VERSION ""

NS_ :

BS_:

BU_:

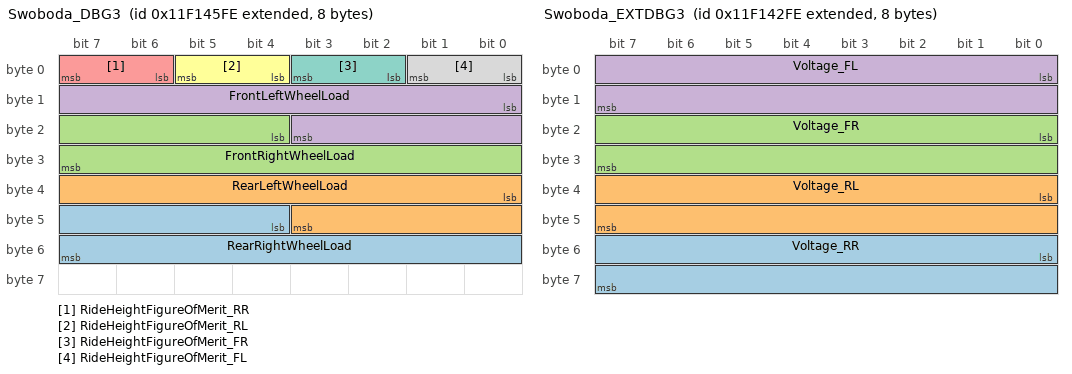
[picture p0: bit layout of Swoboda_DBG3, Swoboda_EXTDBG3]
BO_ 2448508414 Swoboda_DBG3: 8 Vector__XXX
 SG_ RearRightWheelLoad : 44|12@1+ (1,0) [0|4095] "" Vector__XXX
 SG_ RearLeftWheelLoad : 32|12@1+ (1,0) [0|4095] "" Vector__XXX
 SG_ FrontRightWheelLoad : 20|12@1+ (1,0) [0|4095] "" Vector__XXX
 SG_ FrontLeftWheelLoad : 8|12@1+ (1,0) [0|4095] "" Vector__XXX
 SG_ RideHeightFigureOfMerit_RR : 6|2@1+ (1,0) [0|3] "" Vector__XXX
 SG_ RideHeightFigureOfMerit_RL : 4|2@1+ (1,0) [0|3] "" Vector__XXX
 SG_ RideHeightFigureOfMerit_FR : 2|2@1+ (1,0) [0|3] "" Vector__XXX
 SG_ RideHeightFigureOfMerit_FL : 0|2@1+ (1,0) [0|3] "" Vector__XXX

BO_ 2448507646 Swoboda_EXTDBG3: 8 Vector__XXX
 SG_ Voltage_RR : 48|16@1+ (0.0001,0) [0|6.5535] "V" Vector__XXX
 SG_ Voltage_RL : 32|16@1+ (0.0001,0) [0|6.5535] "V" Vector__XXX
 SG_ Voltage_FR : 16|16@1+ (0.0001,0) [0|6.5535] "V" Vector__XXX
 SG_ Voltage_FL : 0|16@1+ (0.0001,0) [0|6.5535] "V" Vector__XXX

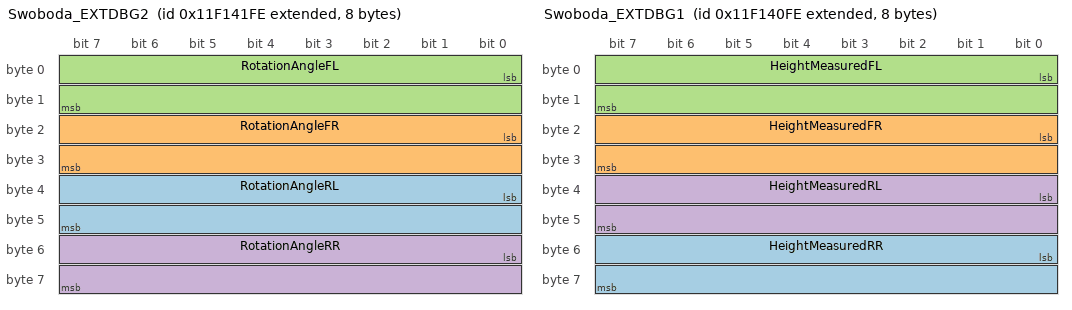
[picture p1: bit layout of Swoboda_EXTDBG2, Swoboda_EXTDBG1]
BO_ 2448507390 Swoboda_EXTDBG2: 8 Vector__XXX
 SG_ RotationAngleRL : 32|16@1+ (0.01,0) [0|360] "deg" Vector__XXX
 SG_ RotationAngleFR : 16|16@1+ (0.01,0) [0|360] "deg" Vector__XXX
 SG_ RotationAngleFL : 0|16@1+ (0.01,0) [0|360] "deg" Vector__XXX
 SG_ RotationAngleRR : 48|16@1+ (0.01,0) [0|360] "deg" Vector__XXX

BO_ 2448507134 Swoboda_EXTDBG1: 8 Vector__XXX
 SG_ HeightMeasuredRR : 48|16@1- (0.01,0) [-327.68|327.67] "mm" Vector__XXX
 SG_ HeightMeasuredFR : 16|16@1- (0.01,0) [-327.68|327.67] "mm" Vector__XXX
 SG_ HeightMeasuredFL : 0|16@1- (0.01,0) [-327.68|327.67] "mm" Vector__XXX
 SG_ HeightMeasuredRL : 32|16@1- (0.01,0) [-327.68|327.67] "mm" Vector__XXX

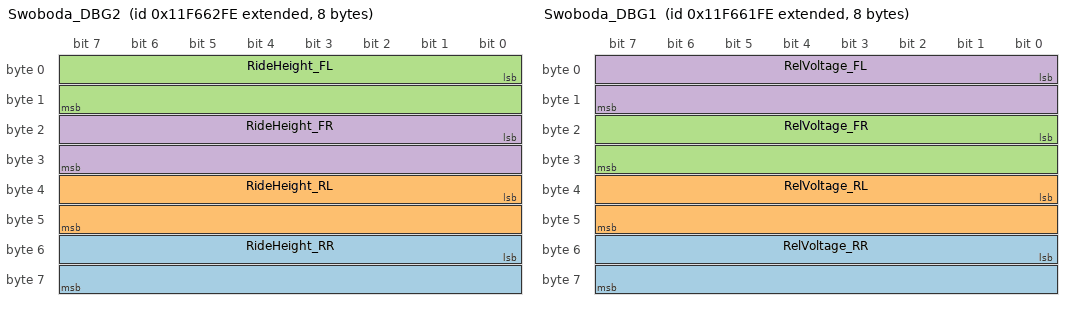
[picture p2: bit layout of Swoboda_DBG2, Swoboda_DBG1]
BO_ 2448843518 Swoboda_DBG2: 8 Vector__XXX
 SG_ RideHeight_RR : 48|16@1- (0.01,0) [-327.68|327.67] "mm" Vector__XXX
 SG_ RideHeight_RL : 32|16@1- (0.01,0) [-327.68|327.67] "mm" Vector__XXX
 SG_ RideHeight_FL : 0|16@1- (0.01,0) [-327.68|327.67] "mm" Vector__XXX
 SG_ RideHeight_FR : 16|16@1- (0.01,0) [-327.68|327.67] "mm" Vector__XXX

BO_ 2448843262 Swoboda_DBG1: 8 Vector__XXX
 SG_ RelVoltage_RR : 48|16@1+ (0.002,0) [0|100] "" Vector__XXX
 SG_ RelVoltage_RL : 32|16@1+ (0.002,0) [0|100] "" Vector__XXX
 SG_ RelVoltage_FR : 16|16@1+ (0.002,0) [0|100] "" Vector__XXX
 SG_ RelVoltage_FL : 0|16@1+ (0.002,0) [0|100] "" Vector__XXX

CM_ SG_ 2448507390 RotationAngleRL "Raw Rotation Angle value which is obtained using the voltage-degree characteristic from Swoboda Ride Height Sensor specification";
CM_ SG_ 2448507390 RotationAngleFR "Raw Rotation Angle value which is obtained using the voltage-degree characteristic from Swoboda Ride Height Sensor specification";
CM_ SG_ 2448507390 RotationAngleFL "Raw Rotation Angle value which is obtained using the voltage-degree characteristic from Swoboda Ride Height Sensor specification";
CM_ SG_ 2448507390 RotationAngleRR "Raw Rotation Angle value which is obtained using the voltage-degree characteristic from Swoboda Ride Height Sensor specification";
CM_ SG_ 2448507134 HeightMeasuredRR "HeightMeasured = L*sin(RotationAngle), where L - sensor lever, default 50 mm accordance to Swoboda Ride Height Sensor specification
offset is not taken into account";
CM_ SG_ 2448507134 HeightMeasuredFR "HeightMeasured = L*sin(RotationAngle), where L - sensor lever, default 50 mm accordance to Swoboda Ride Height Sensor specification
offset is not taken into account";
CM_ SG_ 2448507134 HeightMeasuredFL "HeightMeasured = L*sin(RotationAngle), where L - sensor lever, default 50 mm accordance to Swoboda Ride Height Sensor specification
offset is not taken into account";
CM_ SG_ 2448507134 HeightMeasuredRL "HeightMeasured = L*sin(RotationAngle), where L - sensor lever, default 50 mm accordance to Swoboda Ride Height Sensor specification
offset is not taken into account";
BA_DEF_ BO_  "Producer" STRING ;
BA_DEF_ SG_  "SigType" ENUM  "Default","Range","RangeSigned","ASCII","Discrete","Control","ReferencePGN","DTC","StringDelimiter","StringLength","StringLengthControl","MessageCounter","MessageChecksum";
BA_DEF_ SG_  "GenSigEVName" STRING ;
BA_DEF_ SG_  "GenSigILSupport" ENUM  "No","Yes";
BA_DEF_ SG_  "GenSigSendType" ENUM  "Cyclic","OnWrite","OnWriteWithRepetition","OnChange","OnChangeWithRepetition","IfActive","IfActiveWithRepetition","NoSigSendType";
BA_DEF_ SG_  "GenSigStartValue" INT 0 2147483647;
BA_DEF_ BO_  "GenMsgILSupport" ENUM  "No","Yes";
BA_DEF_ BU_  "NmStationAddress" INT 0 255;
BA_DEF_ BO_  "GenMsgSendType" ENUM  "cyclic","NotUsed","IfActive","NotUsed","NotUsed","NotUsed","NotUsed","NotUsed","noMsgSendType";
BA_DEF_ BO_  "GenMsgRequestable" INT 0 1;
BA_DEF_ BO_  "GenMsgCycleTime" INT 0 3600000;
BA_DEF_  "DBName" STRING ;
BA_DEF_  "BusType" STRING ;
BA_DEF_  "ProtocolType" STRING ;
BA_DEF_ BO_  "VFrameFormat" ENUM  "StandardCAN","ExtendedCAN","reserved","J1939PG";
BA_DEF_DEF_ "Producer" "SCS" ;
BA_DEF_DEF_  "SigType" "Default";
BA_DEF_DEF_  "GenSigEVName" "Env@Nodename_@Signame";
BA_DEF_DEF_  "GenSigILSupport" "Yes";
BA_DEF_DEF_  "GenSigSendType" "NoSigSendType";
BA_DEF_DEF_  "GenSigStartValue" 0;
BA_DEF_DEF_  "GenMsgILSupport" "Yes";
BA_DEF_DEF_  "NmStationAddress" 254;
BA_DEF_DEF_  "GenMsgSendType" "noMsgSendType";
BA_DEF_DEF_  "GenMsgRequestable" 1;
BA_DEF_DEF_  "GenMsgCycleTime" 0;
BA_DEF_DEF_  "DBName" "";
BA_DEF_DEF_  "BusType" "CAN";
BA_DEF_DEF_  "ProtocolType" "J1939";
BA_DEF_DEF_  "VFrameFormat" "J1939PG";
BA_ "DBName" "Payload";
BA_ "GenMsgCycleTime" BO_ 2448508414 1000;
BA_ "GenMsgCycleTime" BO_ 2448507646 1000;
BA_ "GenMsgSendType" BO_ 2448507646 0;
BA_ "GenMsgCycleTime" BO_ 2448507390 1000;
BA_ "GenMsgSendType" BO_ 2448507390 0;
BA_ "GenMsgCycleTime" BO_ 2448507134 1000;
BA_ "GenMsgSendType" BO_ 2448507134 0;
BA_ "GenMsgCycleTime" BO_ 2448843518 1000;
BA_ "GenMsgSendType" BO_ 2448843518 0;
BA_ "GenMsgCycleTime" BO_ 2448843262 1000;
BA_ "GenMsgSendType" BO_ 2448843262 0;
VAL_ 2448508414 RideHeightFigureOfMerit_RR 3 "Ride Height Not Available" 2 "Ride Height Error" 1 "Ride Height degraded" 0 "Ride Height fully functional" ;
VAL_ 2448508414 RideHeightFigureOfMerit_RL 3 "Ride Height Not Available" 2 "Ride Height Error" 1 "Ride Height degraded" 0 "Ride Height fully functional" ;
VAL_ 2448508414 RideHeightFigureOfMerit_FR 3 "Ride Height Not Available" 2 "Ride Height Error" 1 "Ride Height degraded" 0 "Ride Height fully functional" ;
VAL_ 2448508414 RideHeightFigureOfMerit_FL 3 "Ride Height Not Available" 2 "Ride Height Error" 1 "Ride Height degraded" 0 "Ride Height fully functional" ;
